AUTOSAR XML (schema 4-0-3)
package /CalibrationComponents
  parameter sw component type GCFR: data-type-mapping=WorkingDataTypeMappingsSet
    provide port GCFR_Pport: provided-interface=GCFR_if
      provided-com-specs:
        init-value=55, parameter=KeGCFR_Ah_BatteryCellsCap
        init-value=0, parameter=KeLLSR_b_ActiveKeriant_En
        init-value=8, parameter=KeGCFR_Cnt_NumberOfCSC
        init-value=1, parameter=KeGCFR_Cnt_NumberOfCellParal
        init-value=2, parameter=KeGCFR_Cnt_NumberOfWaterThermistors
        init-value=96, parameter=KeGCFR_Cnt_NumberofCells
        init-value=0, parameter=KeGCFR_Cnt_NumberofHeatFilms
        init-value=16, parameter=KeGCFR_Cnt_NumberofTempReadings
        init-value=0, parameter=KeLLSR_k_ActiveKariant_Val
package /GCFR_Code_pkg/GCFR_Code_swc
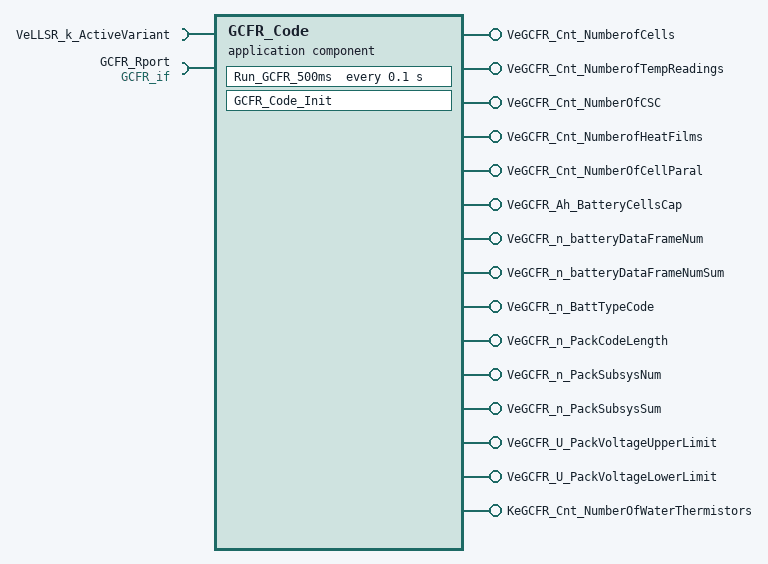
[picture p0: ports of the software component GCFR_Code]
  application sw component type GCFR_Code
    require port VeLLSR_k_ActiveVariant: nonqueued-receiver-com-spec{data-element=VeLLSR_k_ActiveVariant, init-value=0}, required-interface=VeLLSR_k_ActiveVariant
    15 x provide port:
      VeGCFR_Cnt_NumberofCells: provided-interface=VeGCFR_Cnt_NumberofCells
      VeGCFR_Cnt_NumberofTempReadings: provided-interface=VeGCFR_Cnt_NumberofTempReadings
      VeGCFR_Cnt_NumberOfCSC: provided-interface=VeGCFR_Cnt_NumberOfCSC
      VeGCFR_Cnt_NumberofHeatFilms: provided-interface=VeGCFR_Cnt_NumberofHeatFilms
      VeGCFR_Cnt_NumberOfCellParal: provided-interface=VeGCFR_Cnt_NumberOfCellParal
      VeGCFR_Ah_BatteryCellsCap: provided-interface=VeGCFR_Ah_BatteryCellsCap
      VeGCFR_n_batteryDataFrameNum: provided-interface=VeGCFR_n_batteryDataFrameNum
      VeGCFR_n_batteryDataFrameNumSum: provided-interface=VeGCFR_n_batteryDataFrameNumSum
      VeGCFR_n_BattTypeCode: provided-interface=VeGCFR_n_BattTypeCode
      VeGCFR_n_PackCodeLength: provided-interface=VeGCFR_n_PackCodeLength
      VeGCFR_n_PackSubsysNum: provided-interface=VeGCFR_n_PackSubsysNum
      VeGCFR_n_PackSubsysSum: provided-interface=VeGCFR_n_PackSubsysSum
      VeGCFR_U_PackVoltageUpperLimit: provided-interface=VeGCFR_U_PackVoltageUpperLimit
      VeGCFR_U_PackVoltageLowerLimit: provided-interface=VeGCFR_U_PackVoltageLowerLimit
      KeGCFR_Cnt_NumberOfWaterThermistors: provided-interface=KeGCFR_Cnt_NumberOfWaterThermistors
    require port GCFR_Rport: required-interface=GCFR_if
      required-com-specs:
        init-value=55, parameter=KeGCFR_Ah_BatteryCellsCap
        init-value=0, parameter=KeLLSR_b_ActiveKeriant_En
        init-value=8, parameter=KeGCFR_Cnt_NumberOfCSC
        init-value=1, parameter=KeGCFR_Cnt_NumberOfCellParal
        init-value=2, parameter=KeGCFR_Cnt_NumberOfWaterThermistors
        init-value=96, parameter=KeGCFR_Cnt_NumberofCells
        init-value=0, parameter=KeGCFR_Cnt_NumberofHeatFilms
        init-value=16, parameter=KeGCFR_Cnt_NumberofTempReadings
        init-value=0, parameter=KeLLSR_k_ActiveKariant_Val
    behavior GCFR: data-type-mapping=WorkingDataTypeMappingsSet, handle-termination-and-restart=NO-SUPPORT
      constant-memorys:
        28 x parameter data prototype, all with category=ARRAY, sw-calibration-access=READ-WRITE:
          KtSOHR_Ah_AvailableCapacity1_x: type=rt_Array_Float_13, init-value=constant-reference={short-label=KtSOHR_Ah_AvailableCapacity1_x, constant=KtSOHR_Ah_AvailableCapacity1_x}
          KtSOHR_Ah_AvailableCapacity1_y: type=rt_Array_Float_13, init-value=constant-reference={short-label=KtSOHR_Ah_AvailableCapacity1_y, constant=KtSOHR_Ah_AvailableCapacity1_y}
          KtSOHR_Ah_AvailableCapacity2_x: type=rt_Array_Float_13, init-value=constant-reference={short-label=KtSOHR_Ah_AvailableCapacity2_x, constant=KtSOHR_Ah_AvailableCapacity2_x}
          KtSOHR_Ah_AvailableCapacity2_y: type=rt_Array_Float_13, init-value=constant-reference={short-label=KtSOHR_Ah_AvailableCapacity2_y, constant=KtSOHR_Ah_AvailableCapacity2_y}
          KzGCFR_kP_SOC_TempChrgPwrLmt1_x: type=rt_Array_Float_11, init-value=constant-reference={short-label=KzGCFR_kP_SOC_TempChrgPwrLmt1_x, constant=KzGCFR_kP_SOC_TempChrgPwrLmt1_x}
          KzGCFR_kP_SOC_TempChrgPwrLmt1_y: type=rt_Array_Float_13, init-value=constant-reference={short-label=KzGCFR_kP_SOC_TempChrgPwrLmt1_y, constant=KzGCFR_kP_SOC_TempChrgPwrLmt1_y}
          KzGCFR_kP_SOC_TempChrgPwrLmt1_z: type=rt_Array_Float_143, init-value=constant-reference={short-label=KzGCFR_kP_SOC_TempChrgPwrLmt1_z, constant=KzGCFR_kP_SOC_TempChrgPwrLmt1_z}
          KzGCFR_kP_SOC_TempChrgPwrLmt2_x: type=rt_Array_Float_11, init-value=constant-reference={short-label=KzGCFR_kP_SOC_TempChrgPwrLmt2_x, constant=KzGCFR_kP_SOC_TempChrgPwrLmt2_x}
          KzGCFR_kP_SOC_TempChrgPwrLmt2_y: type=rt_Array_Float_13, init-value=constant-reference={short-label=KzGCFR_kP_SOC_TempChrgPwrLmt2_y, constant=KzGCFR_kP_SOC_TempChrgPwrLmt2_y}
          KzGCFR_kP_SOC_TempChrgPwrLmt2_z: type=rt_Array_Float_143, init-value=constant-reference={short-label=KzGCFR_kP_SOC_TempChrgPwrLmt2_z, constant=KzGCFR_kP_SOC_TempChrgPwrLmt2_z}
          KzGCFR_kP_SOC_TempChrgPwrLmtInst1_x: type=rt_Array_Float_11, init-value=constant-reference={short-label=KzGCFR_kP_SOC_TempChrgPwrLmtInst1_x, constant=KzGCFR_kP_SOC_TempChrgPwrLmtInst1_x}
          KzGCFR_kP_SOC_TempChrgPwrLmtInst1_y: type=rt_Array_Float_13, init-value=constant-reference={short-label=KzGCFR_kP_SOC_TempChrgPwrLmtInst1_y, constant=KzGCFR_kP_SOC_TempChrgPwrLmtInst1_y}
          KzGCFR_kP_SOC_TempChrgPwrLmtInst1_z: type=rt_Array_Float_143, init-value=constant-reference={short-label=KzGCFR_kP_SOC_TempChrgPwrLmtInst1_z, constant=KzGCFR_kP_SOC_TempChrgPwrLmtInst1_z}
          KzGCFR_kP_SOC_TempChrgPwrLmtInst2_x: type=rt_Array_Float_11, init-value=constant-reference={short-label=KzGCFR_kP_SOC_TempChrgPwrLmtInst2_x, constant=KzGCFR_kP_SOC_TempChrgPwrLmtInst2_x}
          KzGCFR_kP_SOC_TempChrgPwrLmtInst2_y: type=rt_Array_Float_13, init-value=constant-reference={short-label=KzGCFR_kP_SOC_TempChrgPwrLmtInst2_y, constant=KzGCFR_kP_SOC_TempChrgPwrLmtInst2_y}
          KzGCFR_kP_SOC_TempChrgPwrLmtInst2_z: type=rt_Array_Float_143, init-value=constant-reference={short-label=KzGCFR_kP_SOC_TempChrgPwrLmtInst2_z, constant=KzGCFR_kP_SOC_TempChrgPwrLmtInst2_z}
          KzGCFR_kP_SOC_TempDschgPwrLmt1_x: type=rt_Array_Float_12, init-value=constant-reference={short-label=KzGCFR_kP_SOC_TempDschgPwrLmt1_x, constant=KzGCFR_kP_SOC_TempDschgPwrLmt1_x}
          KzGCFR_kP_SOC_TempDschgPwrLmt1_y: type=rt_Array_Float_14, init-value=constant-reference={short-label=KzGCFR_kP_SOC_TempDschgPwrLmt1_y, constant=KzGCFR_kP_SOC_TempDschgPwrLmt1_y}
          KzGCFR_kP_SOC_TempDschgPwrLmt1_z: type=rt_Array_Float_168, init-value=constant-reference={short-label=KzGCFR_kP_SOC_TempDschgPwrLmt1_z, constant=KzGCFR_kP_SOC_TempDschgPwrLmt1_z}
          KzGCFR_kP_SOC_TempDschgPwrLmt2_x: type=rt_Array_Float_12, init-value=constant-reference={short-label=KzGCFR_kP_SOC_TempDschgPwrLmt2_x, constant=KzGCFR_kP_SOC_TempDschgPwrLmt2_x}
          KzGCFR_kP_SOC_TempDschgPwrLmt2_y: type=rt_Array_Float_14, init-value=constant-reference={short-label=KzGCFR_kP_SOC_TempDschgPwrLmt2_y, constant=KzGCFR_kP_SOC_TempDschgPwrLmt2_y}
          KzGCFR_kP_SOC_TempDschgPwrLmt2_z: type=rt_Array_Float_168, init-value=constant-reference={short-label=KzGCFR_kP_SOC_TempDschgPwrLmt2_z, constant=KzGCFR_kP_SOC_TempDschgPwrLmt2_z}
          KzGCFR_kP_SOC_TempDschgPwrLmtInst1_x: type=rt_Array_Float_12, init-value=constant-reference={short-label=KzGCFR_kP_SOC_TempDschgPwrLmtInst1_x, constant=KzGCFR_kP_SOC_TempDschgPwrLmtInst1_x}
          KzGCFR_kP_SOC_TempDschgPwrLmtInst1_y: type=rt_Array_Float_14, init-value=constant-reference={short-label=KzGCFR_kP_SOC_TempDschgPwrLmtInst1_y, constant=KzGCFR_kP_SOC_TempDschgPwrLmtInst1_y}
          KzGCFR_kP_SOC_TempDschgPwrLmtInst1_z: type=rt_Array_Float_168, init-value=constant-reference={short-label=KzGCFR_kP_SOC_TempDschgPwrLmtInst1_z, constant=KzGCFR_kP_SOC_TempDschgPwrLmtInst1_z}
          KzGCFR_kP_SOC_TempDschgPwrLmtInst2_x: type=rt_Array_Float_12, init-value=constant-reference={short-label=KzGCFR_kP_SOC_TempDschgPwrLmtInst2_x, constant=KzGCFR_kP_SOC_TempDschgPwrLmtInst2_x}
          KzGCFR_kP_SOC_TempDschgPwrLmtInst2_y: type=rt_Array_Float_14, init-value=constant-reference={short-label=KzGCFR_kP_SOC_TempDschgPwrLmtInst2_y, constant=KzGCFR_kP_SOC_TempDschgPwrLmtInst2_y}
          KzGCFR_kP_SOC_TempDschgPwrLmtInst2_z: type=rt_Array_Float_168, init-value=constant-reference={short-label=KzGCFR_kP_SOC_TempDschgPwrLmtInst2_z, constant=KzGCFR_kP_SOC_TempDschgPwrLmtInst2_z}
      static-memorys:
        16 x data, all with sw-calibration-access=READ-ONLY:
          PtSOHR_Ah_AvailableCapacity_x: category=ARRAY, type=rt_Array_Float_13
          PtSOHR_Ah_AvailableCapacity_y: category=ARRAY, type=rt_Array_Float_13
          PzGCFR_kP_SOC_TempChrgPwrLmtInst_z: category=ARRAY, type=rt_Array_Float_143
          PzGCFR_kP_SOC_TempDschgPwrLmtInst_z: category=ARRAY, type=rt_Array_Float_168
          PzGCFR_kP_SOC_TempDschgPwrLmtInst_x: category=ARRAY, type=rt_Array_Float_12
          PzGCFR_kP_SOC_TempDschgPwrLmtInst_y: category=ARRAY, type=rt_Array_Float_14
          PzGCFR_kP_SOC_TempChrgPwrLmt_x: category=ARRAY, type=rt_Array_Float_11
          PzGCFR_kP_SOC_TempChrgPwrLmt_y: category=ARRAY, type=rt_Array_Float_13
          PzGCFR_kP_SOC_TempChrgPwrLmt_z: category=ARRAY, type=rt_Array_Float_143
          PzGCFR_kP_SOC_TempDschgPwrLmt_x: category=ARRAY, type=rt_Array_Float_12
          PzGCFR_kP_SOC_TempDschgPwrLmt_y: category=ARRAY, type=rt_Array_Float_14
          PzGCFR_kP_SOC_TempDschgPwrLmt_z: category=ARRAY, type=rt_Array_Float_168
          PzGCFR_kP_SOC_TempChrgPwrLmtInst_x: category=ARRAY, type=rt_Array_Float_11
          PzGCFR_kP_SOC_TempChrgPwrLmtInst_y: category=ARRAY, type=rt_Array_Float_13
          PeGCFR_k_DriveType: category=VALUE, type=UInt8
          PeGCFR_b_PreHeatSwitchEnable: category=BOOLEAN, type=Boolean
      timing event Event_Run_GCFR_500ms: start-on-event=Run_GCFR_500ms, period=0.1
      runnable GCFR_Code_Init
        data-receive-point-by-arguments:
          access IN_VeLLSR_k_ActiveVariant_VeLLSR_k_ActiveVariant: accessed-variable=VeLLSR_k_ActiveVariant.VeLLSR_k_ActiveVariant
        9 x parameter access:
          CALPRM_GCFR_Rport_KeLLSR_b_ActiveKeriant_En: accessed-parameter=GCFR_Rport.KeLLSR_b_ActiveKeriant_En
          CALPRM_GCFR_Rport_KeLLSR_k_ActiveKariant_Val: accessed-parameter=GCFR_Rport.KeLLSR_k_ActiveKariant_Val
          CALPRM_GCFR_Rport_KeGCFR_Ah_BatteryCellsCap: accessed-parameter=GCFR_Rport.KeGCFR_Ah_BatteryCellsCap
          CALPRM_GCFR_Rport_KeGCFR_Cnt_NumberOfCSC: accessed-parameter=GCFR_Rport.KeGCFR_Cnt_NumberOfCSC
          CALPRM_GCFR_Rport_KeGCFR_Cnt_NumberOfCellParal: accessed-parameter=GCFR_Rport.KeGCFR_Cnt_NumberOfCellParal
          CALPRM_GCFR_Rport_KeGCFR_Cnt_NumberOfWaterThermistors: accessed-parameter=GCFR_Rport.KeGCFR_Cnt_NumberOfWaterThermistors
          CALPRM_GCFR_Rport_KeGCFR_Cnt_NumberofCells: accessed-parameter=GCFR_Rport.KeGCFR_Cnt_NumberofCells
          CALPRM_GCFR_Rport_KeGCFR_Cnt_NumberofHeatFilms: accessed-parameter=GCFR_Rport.KeGCFR_Cnt_NumberofHeatFilms
          CALPRM_GCFR_Rport_KeGCFR_Cnt_NumberofTempReadings: accessed-parameter=GCFR_Rport.KeGCFR_Cnt_NumberofTempReadings
      runnable Run_GCFR_500ms
        7 x parameter access:
          CALPRM_GCFR_Rport_KeGCFR_Ah_BatteryCellsCap: accessed-parameter=GCFR_Rport.KeGCFR_Ah_BatteryCellsCap
          CALPRM_GCFR_Rport_KeGCFR_Cnt_NumberOfCSC: accessed-parameter=GCFR_Rport.KeGCFR_Cnt_NumberOfCSC
          CALPRM_GCFR_Rport_KeGCFR_Cnt_NumberOfCellParal: accessed-parameter=GCFR_Rport.KeGCFR_Cnt_NumberOfCellParal
          CALPRM_GCFR_Rport_KeGCFR_Cnt_NumberOfWaterThermistors: accessed-parameter=GCFR_Rport.KeGCFR_Cnt_NumberOfWaterThermistors
          CALPRM_GCFR_Rport_KeGCFR_Cnt_NumberofCells: accessed-parameter=GCFR_Rport.KeGCFR_Cnt_NumberofCells
          CALPRM_GCFR_Rport_KeGCFR_Cnt_NumberofHeatFilms: accessed-parameter=GCFR_Rport.KeGCFR_Cnt_NumberofHeatFilms
          CALPRM_GCFR_Rport_KeGCFR_Cnt_NumberofTempReadings: accessed-parameter=GCFR_Rport.KeGCFR_Cnt_NumberofTempReadings
